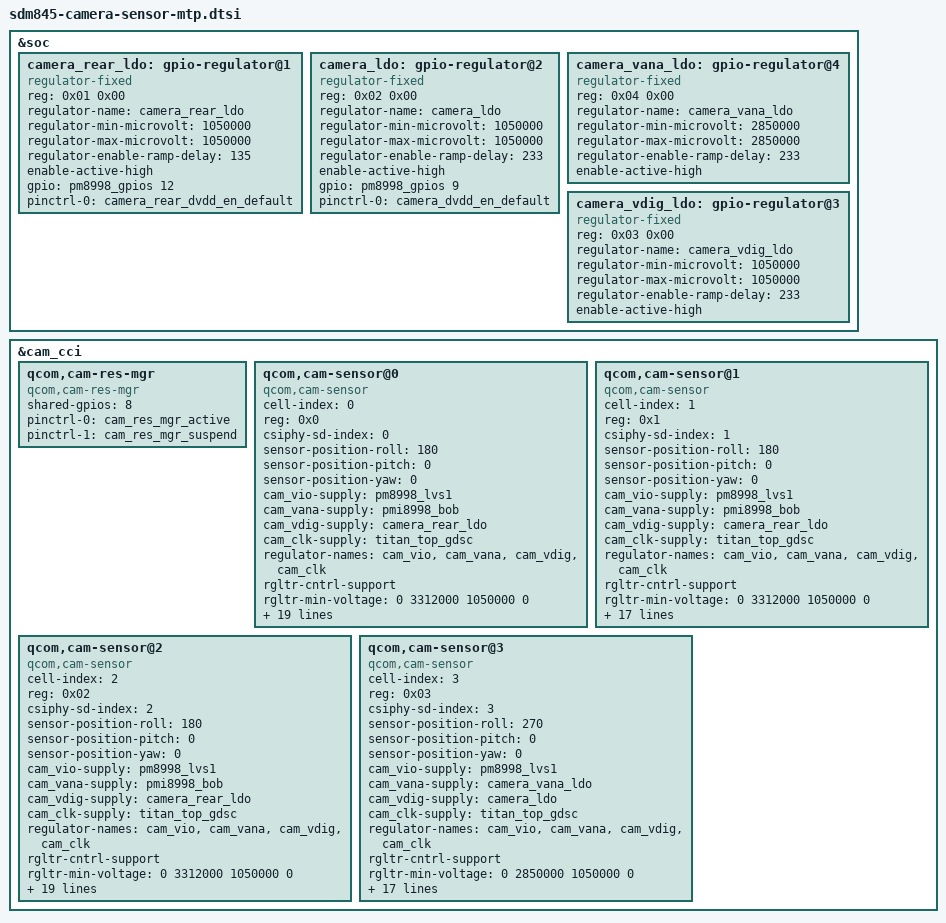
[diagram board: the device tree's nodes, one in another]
/*
 * Copyright (c) 2016-2018, The Linux Foundation. All rights reserved.
 *
 * This program is free software; you can redistribute it and/or modify
 * it under the terms of the GNU General Public License version 2 and
 * only version 2 as published by the Free Software Foundation.
 *
 * This program is distributed in the hope that it will be useful,
 * but WITHOUT ANY WARRANTY; without even the implied warranty of
 * MERCHANTABILITY or FITNESS FOR A PARTICULAR PURPOSE.  See the
 * GNU General Public License for more details.
 */

&soc {
	camera_rear_ldo: gpio-regulator@1 {
		compatible = "regulator-fixed";
		reg = <0x01 0x00>;
		regulator-name = "camera_rear_ldo";
		regulator-min-microvolt = <1050000>;
		regulator-max-microvolt = <1050000>;
		regulator-enable-ramp-delay = <135>;
		enable-active-high;
		gpio = <&pm8998_gpios 12 0>;
		pinctrl-names = "default";
		pinctrl-0 = <&camera_rear_dvdd_en_default>;
		//vin-supply = <&pm8998_s3>;
	};

	camera_ldo: gpio-regulator@2 {
		compatible = "regulator-fixed";
		reg = <0x02 0x00>;
		regulator-name = "camera_ldo";
		regulator-min-microvolt = <1050000>;
		regulator-max-microvolt = <1050000>;
		regulator-enable-ramp-delay = <233>;
		enable-active-high;
		gpio = <&pm8998_gpios 9 0>;
		pinctrl-names = "default";
		pinctrl-0 = <&camera_dvdd_en_default>;
		//vin-supply = <&pm8998_s3>;
	};

	camera_vana_ldo: gpio-regulator@4 {
		compatible = "regulator-fixed";
		reg = <0x04 0x00>;
		regulator-name = "camera_vana_ldo";
		regulator-min-microvolt = <2850000>;
		regulator-max-microvolt = <2850000>;
		regulator-enable-ramp-delay = <233>;
		enable-active-high;
	};
		camera_vdig_ldo: gpio-regulator@3 {
		compatible = "regulator-fixed";
		reg = <0x03 0x00>;
		regulator-name = "camera_vdig_ldo";
		regulator-min-microvolt = <1050000>;
		regulator-max-microvolt = <1050000>;
		regulator-enable-ramp-delay = <233>;
		enable-active-high;
	};
};

&cam_cci {
	qcom,cam-res-mgr {
		compatible = "qcom,cam-res-mgr";
		status = "ok";
		shared-gpios = <8>;
		pinctrl-names = "cam_res_mgr_default", "cam_res_mgr_suspend";
		pinctrl-0 = <&cam_res_mgr_active>;
		pinctrl-1 = <&cam_res_mgr_suspend>;
	};

	qcom,cam-sensor@0 {
		cell-index = <0>;
		compatible = "qcom,cam-sensor";
		reg = <0x0>;
		csiphy-sd-index = <0>;
		sensor-position-roll = <180>;
		sensor-position-pitch = <0>;
		sensor-position-yaw = <0>;
		cam_vio-supply = <&pm8998_lvs1>;
		cam_vana-supply = <&pmi8998_bob>;
		cam_vdig-supply = <&camera_rear_ldo>;
		cam_clk-supply = <&titan_top_gdsc>;
		regulator-names = "cam_vio", "cam_vana", "cam_vdig", "cam_clk";
		rgltr-cntrl-support;
		rgltr-min-voltage = <0 3312000 1050000 0>;
		rgltr-max-voltage = <0 3600000 1050000 0>;
		rgltr-load-current = <0 80000 105000 0>;
		gpio-no-mux = <0>;
		pinctrl-names = "cam_default", "cam_suspend";
		pinctrl-0 = <&cam_sensor_mclk0_active
				&cam_sensor_rear_active>;
		pinctrl-1 = <&cam_sensor_mclk0_suspend
				&cam_sensor_rear_suspend>;
		gpios = <&tlmm 13 0>,
			<&tlmm 9 0>,
			<&tlmm 8 0>;
		gpio-reset = <1>;
		gpio-vana = <2>;
		gpio-req-tbl-num = <0 1 2>;
		gpio-req-tbl-flags = <1 0 0>;
		gpio-req-tbl-label = "CAMIF_MCLK0", "CAM_RESET0", "CAM_VANA0";
		sensor-mode = <0>;
		cci-master = <0>;
		status = "ok";
		clocks = <&clock_camcc CAM_CC_MCLK0_CLK>;
		clock-names = "cam_clk";
		clock-cntl-level = "turbo";
		clock-rates = <24000000>;
	};

	qcom,cam-sensor@1 {
		cell-index = <1>;
		compatible = "qcom,cam-sensor";
		reg = <0x1>;
		csiphy-sd-index = <1>;
		sensor-position-roll = <180>;
		sensor-position-pitch = <0>;
		sensor-position-yaw = <0>;
		cam_vio-supply = <&pm8998_lvs1>;
		cam_vana-supply = <&pmi8998_bob>;
		cam_vdig-supply = <&camera_rear_ldo>;
		cam_clk-supply = <&titan_top_gdsc>;
		regulator-names = "cam_vio", "cam_vana", "cam_vdig", "cam_clk";
		rgltr-cntrl-support;
		rgltr-min-voltage = <0 3312000 1050000 0>;
		rgltr-max-voltage = <0 3600000 1050000 0>;
		rgltr-load-current = <0 80000 105000 0>;
		gpio-no-mux = <0>;
		pinctrl-names = "cam_default", "cam_suspend";
		pinctrl-0 = <&cam_sensor_mclk1_active>;
				//&cam_sensor_rear_active>;
		pinctrl-1 = <&cam_sensor_mclk1_suspend>;
				//&cam_sensor_rear_suspend>;
		gpios = <&tlmm 14 0>,
			<&tlmm 7 0>,
			<&tlmm 8 0>; // all vana0
			//<&tlmm 84 0>;
		gpio-reset = <1>;
		gpio-vana = <2>;
		gpio-req-tbl-num = <0 1 2>;
		gpio-req-tbl-flags = <1 0 0>;
		gpio-req-tbl-label = "CAMIF_MCLK1", "CAM_RESET1", "CAM_VANA1";
		sensor-mode = <0>;
		cci-master = <0>;
		status = "ok";
		clocks = <&clock_camcc CAM_CC_MCLK1_CLK>;
		clock-names = "cam_clk";
		clock-cntl-level = "turbo";
		clock-rates = <24000000>;
	};

	qcom,cam-sensor@2 {
		cell-index = <2>;
		compatible = "qcom,cam-sensor";
		reg = <0x02>;
		csiphy-sd-index = <2>;
		sensor-position-roll = <180>;
		sensor-position-pitch = <0>;
		sensor-position-yaw = <0>;
		cam_vio-supply = <&pm8998_lvs1>;
		cam_vana-supply = <&pmi8998_bob>;
		cam_vdig-supply = <&camera_rear_ldo>;
		cam_clk-supply = <&titan_top_gdsc>;
		regulator-names = "cam_vio", "cam_vana", "cam_vdig", "cam_clk";
		rgltr-cntrl-support;
		rgltr-min-voltage = <0 3312000 1050000 0>;
		rgltr-max-voltage = <0 3600000 1050000 0>;
		rgltr-load-current = <0 80000 105000 0>;
		gpio-no-mux = <0>;
		pinctrl-names = "cam_default", "cam_suspend";
		pinctrl-0 = <&cam_sensor_mclk2_active
				 &cam_sensor_front_active>;
		pinctrl-1 = <&cam_sensor_mclk2_suspend
				 &cam_sensor_front_suspend>;
		gpios = <&tlmm 15 0>,
			<&tlmm 12 0>,
			<&tlmm 8 0>; // all vana0
		gpio-reset = <1>;
		gpio-vana = <2>;
		gpio-req-tbl-num = <0 1 2>;
		gpio-req-tbl-flags = <1 0 0>;
		gpio-req-tbl-label = "CAMIF_MCLK2", "CAM_RESET2", "CAM_VANA2";
		sensor-mode = <0>;
		cci-master = <1>;
		status = "ok";
		clocks = <&clock_camcc CAM_CC_MCLK2_CLK>;
		clock-names = "cam_clk";
		clock-cntl-level = "turbo";
		clock-rates = <24000000>;
	};

	qcom,cam-sensor@3 {
		cell-index = <3>;
		compatible = "qcom,cam-sensor";
		reg = <0x03>;
		csiphy-sd-index = <3>;
		sensor-position-roll = <270>;
		sensor-position-pitch = <0>;
		sensor-position-yaw = <0>;
		cam_vio-supply = <&pm8998_lvs1>;
		cam_vana-supply = <&camera_vana_ldo>;
		cam_vdig-supply = <&camera_ldo>;
		cam_clk-supply = <&titan_top_gdsc>;
		regulator-names = "cam_vio", "cam_vana", "cam_vdig", "cam_clk";
		rgltr-cntrl-support;
		rgltr-min-voltage = <0 2850000 1050000 0>;
		rgltr-max-voltage = <0 2850000 1050000 0>;
		rgltr-load-current = <0 80000 105000 0>;
		gpio-no-mux = <0>;
		pinctrl-names = "cam_default", "cam_suspend";
		pinctrl-0 = <&cam_sensor_mclk3_active
				 &cam_sensor_iris_active>;
		pinctrl-1 = <&cam_sensor_mclk3_suspend
				 &cam_sensor_iris_suspend>;
		gpios = <&tlmm 16 0>,
			<&tlmm 9 0>;
		gpio-reset = <1>;
		gpio-req-tbl-num = <0 1>;
		gpio-req-tbl-flags = <1 0>;
		gpio-req-tbl-label = "CAMIF_MCLK3", "CAM_RESET3";
		sensor-mode = <0>;
		cci-master = <1>;
		status = "ok";
		clocks = <&clock_camcc CAM_CC_MCLK3_CLK>;
		clock-names = "cam_clk";
		clock-cntl-level = "turbo";
		clock-rates = <24000000>;
	};
};
